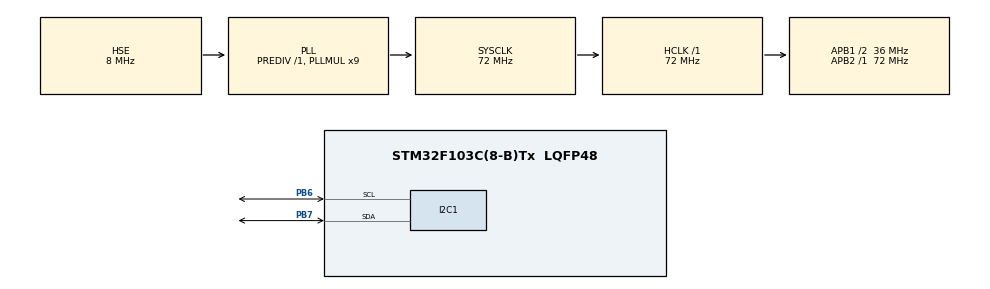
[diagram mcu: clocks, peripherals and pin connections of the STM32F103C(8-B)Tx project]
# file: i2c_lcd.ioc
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Mcu.Family=STM32F1
Mcu.Name=STM32F103C(8-B)Tx
Mcu.Package=LQFP48
NVIC.PriorityGroup=NVIC_PRIORITYGROUP_4
PA13.Mode=Serial_Wire
PA13.Signal=SYS_JTMS-SWDIO
PA14.Mode=Serial_Wire
PA14.Signal=SYS_JTCK-SWCLK
PB6.Mode=I2C
PB6.Signal=I2C1_SCL
PB7.Mode=I2C
PB7.Signal=I2C1_SDA
PD0-OSC_IN.Mode=HSE-External-Oscillator
PD0-OSC_IN.Signal=RCC_OSC_IN
PD1-OSC_OUT.Mode=HSE-External-Oscillator
PD1-OSC_OUT.Signal=RCC_OSC_OUT
ProjectManager.HeapSize=0x200
ProjectManager.StackSize=0x400
ProjectManager.TargetToolchain=STM32CubeIDE
RCC.AHBFreq_Value=72000000
RCC.APB1CLKDivider=RCC_HCLK_DIV2
RCC.APB1Freq_Value=36000000
RCC.APB1TimFreq_Value=72000000
RCC.APB2Freq_Value=72000000
RCC.APB2TimFreq_Value=72000000
RCC.HCLKFreq_Value=72000000
RCC.PLLMUL=RCC_PLL_MUL9
RCC.PLLSourceVirtual=RCC_PLLSOURCE_HSE
RCC.SYSCLKFreq_VALUE=72000000
RCC.SYSCLKSource=RCC_SYSCLKSOURCE_PLLCLK
RCC.USBFreq_Value=72000000
board=custom

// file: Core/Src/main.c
/* USER CODE BEGIN Header */
/**
  ******************************************************************************
  * @file           : main.c
  * @brief          : Main program body
  ******************************************************************************
  * @attention
  *
  * Copyright (c) 2023 STMicroelectronics.
  * All rights reserved.
  *
  * This software is licensed under terms that can be found in the LICENSE file
  * in the root directory of this software component.
  * If no LICENSE file comes with this software, it is provided AS-IS.
  *
  ******************************************************************************
  */
/* USER CODE END Header */
#include "main.h"
#include "stdio.h"
#include "i2c-lcd.h"

I2C_HandleTypeDef hi2c1;

void SystemClock_Config(void);
static void MX_GPIO_Init(void);
static void MX_I2C1_Init(void);

/* USER CODE BEGIN 0 */
#define DS3231_ADDRESS 0xD0

// Convert normal decimal numbers to binary coded decimal
uint8_t decToBcd(int val)
{
  return (uint8_t)( (val/10*16) + (val%10) );
}
// Convert binary coded decimal to normal decimal numbers
int bcdToDec(uint8_t val)
{
  return (int)( (val/16*10) + (val%16) );
}

typedef struct {
	uint8_t seconds;
	uint8_t minutes;
	uint8_t hour;
	uint8_t dayofweek;
	uint8_t dayofmonth;
	uint8_t month;
	uint8_t year;
} TIME;

TIME time;

//function to set time

void set_time(uint8_t sec,uint8_t min, uint8_t hour, uint8_t dow, uint8_t dom, uint8_t month, uint8_t year)
{
	uint8_t set_time[7];
	set_time[0] = bcdToDec(sec);
	set_time[1] = bcdToDec(sec);
	set_time[2] = bcdToDec(sec);
	set_time[3] = bcdToDec(sec);
	set_time[4] = bcdToDec(sec);
	set_time[5] = bcdToDec(sec);
	set_time[6] = bcdToDec(sec);

	HAL_I2C_Mem_Write(&hi2c1, DS3231_ADDRESS, 0x00, 1, set_time, 7, 1000);
}

void Get_Time (void)
{
	uint8_t get_time[7];
	HAL_I2C_Mem_Read(&hi2c1, DS3231_ADDRESS, 0x00, 1, get_time, 7, 1000);
	time.seconds = bcdToDec(get_time[0]);
	time.minutes = bcdToDec(get_time[1]);
	time.hour = bcdToDec(get_time[2]);
	time.dayofweek = bcdToDec(get_time[3]);
	time.dayofmonth = bcdToDec(get_time[4]);
	time.month = bcdToDec(get_time[5]);
	time.year = bcdToDec(get_time[6]);
}

float Get_Temp (void)
{
	uint8_t temp[2];

	HAL_I2C_Mem_Read(&hi2c1, DS3231_ADDRESS, 0x11, 1, temp, 2, 1000);
	return ((temp[0])+(temp[1]>>6)/4.0);
}

void force_temp_conv (void)
{
	uint8_t status=0;
	uint8_t control=0;
	HAL_I2C_Mem_Read(&hi2c1, DS3231_ADDRESS, 0x0F, 1, &status, 1, 100);  // read status register
	if (!(status&0x04))
	{
		HAL_I2C_Mem_Read(&hi2c1, DS3231_ADDRESS, 0x0E, 1, &control, 1, 100);  // read control register
		HAL_I2C_Mem_Write(&hi2c1, DS3231_ADDRESS, 0x0E, 1, (uint8_t *)(control|(0x20)), 1, 100);
	}
}

float TEMP;
char buffer[15];
/* USER CODE END 0 */

int main(void)
{

  /* MCU Configuration--------------------------------------------------------*/

  /* Reset of all peripherals, Initializes the Flash interface and the Systick. */
  HAL_Init();

  /* Configure the system clock */
  SystemClock_Config();

  /* Initialize all configured peripherals */
  MX_GPIO_Init();
  MX_I2C1_Init();
  /* USER CODE BEGIN 2 */
  lcd_init();
  set_time(00, 35, 13, 5, 3, 1, 19);
  /* USER CODE END 2 */

  /* Infinite loop */
  while (1)
  {
	 Get_Time();
	 sprintf (buffer, "%02d:%02d:%02d", time.hour, time.minutes, time.seconds);
	 lcd_put_cur (0,0);
	 lcd_send_string(buffer);

	 sprintf (buffer, "%02d-%02d-20%02d", time.dayofmonth, time.month, time.year);
	 lcd_put_cur(1, 0);
	 lcd_send_string(buffer);

	 force_temp_conv();

	 TEMP = Get_Temp();

	 lcd_put_cur(0, 10);

	 sprintf (buffer, "%f", TEMP);

	 lcd_send_string(buffer);

	 HAL_Delay(500);
  }
}

void SystemClock_Config(void)
{
  RCC_OscInitTypeDef RCC_OscInitStruct = {0};
  RCC_ClkInitTypeDef RCC_ClkInitStruct = {0};

  /** Initializes the RCC Oscillators according to the specified parameters
  * in the RCC_OscInitTypeDef structure.
  */
  RCC_OscInitStruct.OscillatorType = RCC_OSCILLATORTYPE_HSE;
  RCC_OscInitStruct.HSEState = RCC_HSE_ON;
  RCC_OscInitStruct.HSEPredivValue = RCC_HSE_PREDIV_DIV1;
  RCC_OscInitStruct.HSIState = RCC_HSI_ON;
  RCC_OscInitStruct.PLL.PLLState = RCC_PLL_ON;
  RCC_OscInitStruct.PLL.PLLSource = RCC_PLLSOURCE_HSE;
  RCC_OscInitStruct.PLL.PLLMUL = RCC_PLL_MUL9;
  if (HAL_RCC_OscConfig(&RCC_OscInitStruct) != HAL_OK)
  {
    Error_Handler();
  }

  /** Initializes the CPU, AHB and APB buses clocks
  */
  RCC_ClkInitStruct.ClockType = RCC_CLOCKTYPE_HCLK|RCC_CLOCKTYPE_SYSCLK
                              |RCC_CLOCKTYPE_PCLK1|RCC_CLOCKTYPE_PCLK2;
  RCC_ClkInitStruct.SYSCLKSource = RCC_SYSCLKSOURCE_PLLCLK;
  RCC_ClkInitStruct.AHBCLKDivider = RCC_SYSCLK_DIV1;
  RCC_ClkInitStruct.APB1CLKDivider = RCC_HCLK_DIV2;
  RCC_ClkInitStruct.APB2CLKDivider = RCC_HCLK_DIV1;

  if (HAL_RCC_ClockConfig(&RCC_ClkInitStruct, FLASH_LATENCY_2) != HAL_OK)
  {
    Error_Handler();
  }
}

static void MX_I2C1_Init(void)
{

  hi2c1.Instance = I2C1;
  hi2c1.Init.ClockSpeed = 100000;
  hi2c1.Init.DutyCycle = I2C_DUTYCYCLE_2;
  hi2c1.Init.OwnAddress1 = 0;
  hi2c1.Init.AddressingMode = I2C_ADDRESSINGMODE_7BIT;
  hi2c1.Init.DualAddressMode = I2C_DUALADDRESS_DISABLE;
  hi2c1.Init.OwnAddress2 = 0;
  hi2c1.Init.GeneralCallMode = I2C_GENERALCALL_DISABLE;
  hi2c1.Init.NoStretchMode = I2C_NOSTRETCH_DISABLE;
  if (HAL_I2C_Init(&hi2c1) != HAL_OK)
  {
    Error_Handler();
  }

}

static void MX_GPIO_Init(void)
{

  /* GPIO Ports Clock Enable */
  __HAL_RCC_GPIOD_CLK_ENABLE();
  __HAL_RCC_GPIOA_CLK_ENABLE();
  __HAL_RCC_GPIOB_CLK_ENABLE();

}

void Error_Handler(void)
{
  __disable_irq();
  while (1)
  {
  }
}
